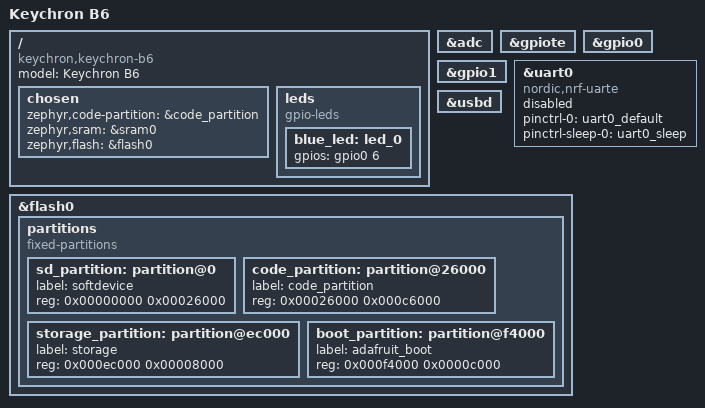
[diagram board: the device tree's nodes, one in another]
// Keychron B6 – nRF52840
/dts-v1/;
#include <nordic/nrf52840_qiaa.dtsi>
#include "keychron_b6-pinctrl.dtsi"

/ {
    model = "Keychron B6";
    compatible = "keychron,keychron-b6";

    chosen {
        zephyr,code-partition = &code_partition;
        zephyr,sram = &sram0;
        zephyr,flash = &flash0;
    };

    leds {
        compatible = "gpio-leds";
        blue_led: led_0 {
            gpios = <&gpio0 6 GPIO_ACTIVE_HIGH>;
        };
    };
};

&adc {
    status = "okay";
};

&gpiote {
    status = "okay";
};

&gpio0 {
    status = "okay";
};

&gpio1 {
    status = "okay";
};

&uart0 {
    compatible = "nordic,nrf-uarte";
    status = "disabled";
    pinctrl-0 = <&uart0_default>;
    pinctrl-sleep-0 = <&uart0_sleep>;
    pinctrl-names = "default", "sleep";
};

&usbd {
    status = "okay";
};

&flash0 {
    partitions {
        compatible = "fixed-partitions";
        #address-cells = <1>;
        #size-cells = <1>;

        sd_partition: partition@0 {
            label = "softdevice";
            reg = <0x00000000 0x00026000>;
        };
        code_partition: partition@26000 {
            label = "code_partition";
            reg = <0x00026000 0x000c6000>;
        };
        storage_partition: partition@ec000 {
            label = "storage";
            reg = <0x000ec000 0x00008000>;
        };
        boot_partition: partition@f4000 {
            label = "adafruit_boot";
            reg = <0x000f4000 0x0000c000>;
        };
    };
};
